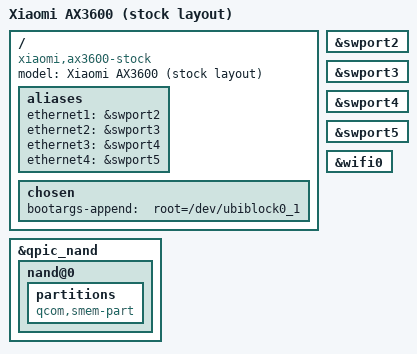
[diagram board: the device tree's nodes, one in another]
// SPDX-License-Identifier: GPL-2.0-or-later OR MIT

/dts-v1/;

#include "ipq8071-ax3600.dts"

/ {
	model = "Xiaomi AX3600 (stock layout)";
	compatible = "xiaomi,ax3600-stock", "qcom,ipq8074";

	aliases {
		ethernet1 = &swport2;
		ethernet2 = &swport3;
		ethernet3 = &swport4;
		ethernet4 = &swport5;
	};

	chosen {
		bootargs-append = " root=/dev/ubiblock0_1";
	};
};

&qpic_nand {
	/delete-node/ partitions;

	nand@0 {
		/delete-node/ partitions;

		partitions {
			compatible = "qcom,smem-part";
		};
	};
};

&swport2 {
	/delete-property/ nvmem-cells;
	/delete-property/ nvmem-cell-names;
};

&swport3 {
	/delete-property/ nvmem-cells;
	/delete-property/ nvmem-cell-names;
};

&swport4 {
	/delete-property/ nvmem-cells;
	/delete-property/ nvmem-cell-names;
};

&swport5 {
	/delete-property/ nvmem-cells;
	/delete-property/ nvmem-cell-names;
};

&wifi0 {
	/delete-property/ nvmem-cells;
	/delete-property/ nvmem-cell-names;
};
